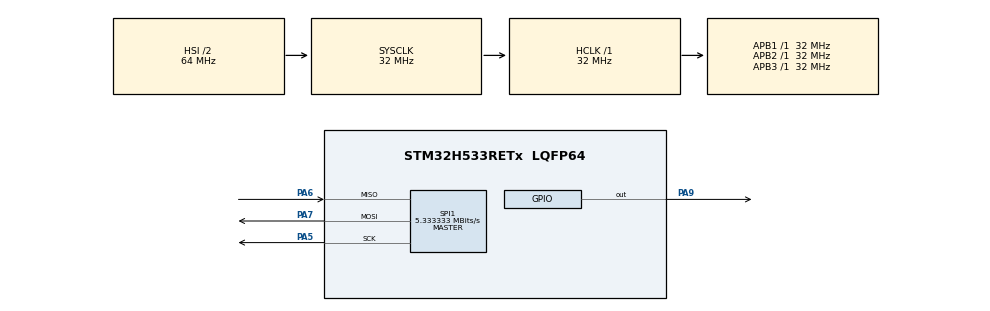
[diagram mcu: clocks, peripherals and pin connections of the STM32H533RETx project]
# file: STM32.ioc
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BOOTPATH.BootPathName=LEGACY
BOOTPATH.UserSelectedBootPath=LEGACY
CORTEX_M33_NS.Number-Cortex_Memory_Protection_Unit_Region0_OTP_RO_AREAS_Settings=MPU_REGION_NUMBER0
CORTEX_M33_NS.default_mode_Activation=1
CORTEX_M33_NS.userName=CORTEX_M33
Mcu.Family=STM32H5
Mcu.Name=STM32H533RETx
Mcu.Package=LQFP64
NUCLEO-H533RE.BUTTON=1
NUCLEO-H533RE.LD4=true
NUCLEO-H533RE.VCP=true
NVIC.EXTI13_IRQn=true\:0\:0\:false\:false\:true\:false\:true\:true
NVIC.PriorityGroup=NVIC_PRIORITYGROUP_4
PA13(JTMS/SWDIO).GPIO_Label=SWDIO
PA13(JTMS/SWDIO).Signal=DEBUG_JTMS-SWDIO
PA14(JTCK/SWCLK).GPIO_Label=SWCLK
PA14(JTCK/SWCLK).Signal=DEBUG_JTCK-SWCLK
PA15(JTDI).GPIO_Label=JTDI
PA15(JTDI).Signal=DEBUG_JTDI
PA2.Signal=USART2_TX
PA3.Signal=USART2_RX
PA5.Mode=Full_Duplex_Master
PA5.Signal=SPI1_SCK
PA6.Mode=Full_Duplex_Master
PA6.Signal=SPI1_MISO
PA7.Mode=Full_Duplex_Master
PA7.Signal=SPI1_MOSI
PA9.PinState=GPIO_PIN_SET
PA9.Signal=GPIO_Output
PB3(JTDO/TRACESWO).GPIO_Label=SWO
PB3(JTDO/TRACESWO).Signal=DEBUG_JTDO-SWO
ProjectManager.HeapSize=0x200
ProjectManager.StackSize=0x400
ProjectManager.TargetToolchain=CMake
RCC.ADCFreq_Value=32000000
RCC.AHBFreq_Value=32000000
RCC.APB1Freq_Value=32000000
RCC.APB1TimFreq_Value=32000000
RCC.APB2Freq_Value=32000000
RCC.APB2TimFreq_Value=32000000
RCC.APB3Freq_Value=32000000
RCC.CSI_VALUE=4000000
RCC.CortexFreq_Value=32000000
RCC.EPOD_VALUE=4000000
RCC.HCLKFreq_Value=32000000
RCC.HSE_VALUE=25000000
RCC.HSI48_VALUE=48000000
RCC.HSI_VALUE=64000000
RCC.LSE_VALUE=32768
RCC.LSIRC_VALUE=32000
RCC.PLL1Q=3
RCC.PLLFRACN=0
RCC.PLLN=32
RCC.SYSCLKFreq_VALUE=32000000
RCC.USBFreq_Value=48000000
RCC.VCOOutputFreq_Value=128000000
SPI1.BaudRatePrescaler=SPI_BAUDRATEPRESCALER_8
SPI1.CRCCalculation=SPI_CRCCALCULATION_DISABLE
SPI1.CalculateBaudRate=5.333333 MBits/s
SPI1.DataSize=SPI_DATASIZE_8BIT
SPI1.Direction=SPI_DIRECTION_2LINES
SPI1.MasterKeepIOState=SPI_MASTER_KEEP_IO_STATE_ENABLE
SPI1.MasterSSIdleness=SPI_MASTER_SS_IDLENESS_00CYCLE
SPI1.Mode=SPI_MODE_MASTER
SPI1.NSSPMode=SPI_NSS_PULSE_DISABLE
SPI1.VirtualType=VM_MASTER
VP_BOOTPATH_VS_BOOTPATH.Mode=BP_Activate
VP_CORTEX_M33_NS_VS_Hclk.Mode=Hclk_Mode
VP_ICACHE_VS_ICACHE.Mode=DirectMappedCache
VP_MEMORYMAP_VS_MEMORYMAP.Mode=CurAppReg
VP_NUCLEO-H533RE_VS_BSP_COMMON.Mode=COMMON
VP_PWR_VS_LPOM.Mode=PowerOptimisation
VP_PWR_VS_SECSignals.Mode=Security/Privilege
board=NUCLEO-H533RE

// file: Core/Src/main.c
/* USER CODE BEGIN Header */
/**
 ******************************************************************************
 * @file           : main.c
 * @brief          : Main program body
 ******************************************************************************
 * @attention
 *
 * Copyright (c) 2026 STMicroelectronics.
 * All rights reserved.
 *
 * This software is licensed under terms that can be found in the LICENSE file
 * in the root directory of this software component.
 * If no LICENSE file comes with this software, it is provided AS-IS.
 *
 ******************************************************************************
 */
/* USER CODE END Header */
#include "main.h"

/* USER CODE BEGIN Includes */
#include "../Inc/adxl367.h"
#include "../Inc/protocol.h"
#include "../Inc/uart.h"

/* USER CODE END Includes */

COM_InitTypeDef BspCOMInit;

SPI_HandleTypeDef hspi1;

void SystemClock_Config(void);
static void MPU_Config(void);
static void MX_GPIO_Init(void);
static void MX_ICACHE_Init(void);
static void MX_SPI1_Init(void);

int main(void) {

    /* MCU
     * Configuration--------------------------------------------------------*/

    /* MPU
     * Configuration--------------------------------------------------------*/
    MPU_Config();

    /* Reset of all peripherals, Initializes the Flash interface and the
     * Systick. */
    HAL_Init();

    /* Configure the system clock */
    SystemClock_Config();

    /* Initialize all configured peripherals */
    MX_GPIO_Init();
    MX_ICACHE_Init();
    MX_SPI1_Init();

    /* Initialize USER push-button, will be used to trigger an interrupt each
     * time it's pressed.*/
    BSP_PB_Init(BUTTON_USER, BUTTON_MODE_EXTI);

    /* Initialize COM1 port (115200, 8 bits (7-bit data + 1 stop bit), no parity
     */
    BspCOMInit.BaudRate = 115200;
    BspCOMInit.WordLength = COM_WORDLENGTH_8B;
    BspCOMInit.StopBits = COM_STOPBITS_1;
    BspCOMInit.Parity = COM_PARITY_NONE;
    BspCOMInit.HwFlowCtl = COM_HWCONTROL_NONE;
    if (BSP_COM_Init(COM1, &BspCOMInit) != BSP_ERROR_NONE) {
        Error_Handler();
    }

    /* Validate ADXL367 device id
     */
    uint8_t ADXL_Devid = 0;
    ADXL_Op(&hspi1, ADXL_READ, ADXL_DEVID_AD, &ADXL_Devid);

    ADXL_Init_Measure_Mode(&hspi1);

    uint8_t next_packet_seq = 0;
    /* Main Loop
     */
    while (1) {
        uint8_t data[6] = {};
        ADXL_Capture_Data(&hspi1, data);

        uint8_t* packet = Create_Packet(data, next_packet_seq);
        next_packet_seq = (next_packet_seq + 1) % 256;

        UART_Transmit(&hcom_uart[COM1], packet, 11);

        HAL_Delay(2.5);
    }
}

void SystemClock_Config(void) {
    RCC_OscInitTypeDef RCC_OscInitStruct = {0};
    RCC_ClkInitTypeDef RCC_ClkInitStruct = {0};

    /** Configure the main internal regulator output voltage
     */
    __HAL_PWR_VOLTAGESCALING_CONFIG(PWR_REGULATOR_VOLTAGE_SCALE3);

    while (!__HAL_PWR_GET_FLAG(PWR_FLAG_VOSRDY)) {
    }

    /** Initializes the RCC Oscillators according to the specified
     * parameters in the RCC_OscInitTypeDef structure.
     */
    RCC_OscInitStruct.OscillatorType =
        RCC_OSCILLATORTYPE_HSI | RCC_OSCILLATORTYPE_CSI;
    RCC_OscInitStruct.HSIState = RCC_HSI_ON;
    RCC_OscInitStruct.HSIDiv = RCC_HSI_DIV2;
    RCC_OscInitStruct.HSICalibrationValue = RCC_HSICALIBRATION_DEFAULT;
    RCC_OscInitStruct.CSIState = RCC_CSI_ON;
    RCC_OscInitStruct.CSICalibrationValue = RCC_CSICALIBRATION_DEFAULT;
    RCC_OscInitStruct.PLL.PLLState = RCC_PLL_ON;
    RCC_OscInitStruct.PLL.PLLSource = RCC_PLL1_SOURCE_CSI;
    RCC_OscInitStruct.PLL.PLLM = 1;
    RCC_OscInitStruct.PLL.PLLN = 32;
    RCC_OscInitStruct.PLL.PLLP = 2;
    RCC_OscInitStruct.PLL.PLLQ = 3;
    RCC_OscInitStruct.PLL.PLLR = 2;
    RCC_OscInitStruct.PLL.PLLRGE = RCC_PLL1_VCIRANGE_2;
    RCC_OscInitStruct.PLL.PLLVCOSEL = RCC_PLL1_VCORANGE_WIDE;
    RCC_OscInitStruct.PLL.PLLFRACN = 0;
    if (HAL_RCC_OscConfig(&RCC_OscInitStruct) != HAL_OK) {
        Error_Handler();
    }

    /** Initializes the CPU, AHB and APB buses clocks
     */
    RCC_ClkInitStruct.ClockType = RCC_CLOCKTYPE_HCLK | RCC_CLOCKTYPE_SYSCLK |
                                  RCC_CLOCKTYPE_PCLK1 | RCC_CLOCKTYPE_PCLK2 |
                                  RCC_CLOCKTYPE_PCLK3;
    RCC_ClkInitStruct.SYSCLKSource = RCC_SYSCLKSOURCE_HSI;
    RCC_ClkInitStruct.AHBCLKDivider = RCC_SYSCLK_DIV1;
    RCC_ClkInitStruct.APB1CLKDivider = RCC_HCLK_DIV1;
    RCC_ClkInitStruct.APB2CLKDivider = RCC_HCLK_DIV1;
    RCC_ClkInitStruct.APB3CLKDivider = RCC_HCLK_DIV1;

    if (HAL_RCC_ClockConfig(&RCC_ClkInitStruct, FLASH_LATENCY_1) != HAL_OK) {
        Error_Handler();
    }

    /** Configure the programming delay
     */
    __HAL_FLASH_SET_PROGRAM_DELAY(FLASH_PROGRAMMING_DELAY_0);
}

static void MX_ICACHE_Init(void) {

    /** Enable instruction cache in 1-way (direct mapped cache)
     */
    if (HAL_ICACHE_ConfigAssociativityMode(ICACHE_1WAY) != HAL_OK) {
        Error_Handler();
    }
    if (HAL_ICACHE_Enable() != HAL_OK) {
        Error_Handler();
    }
}

static void MX_SPI1_Init(void) {

    /* SPI1 parameter configuration*/
    hspi1.Instance = SPI1;
    hspi1.Init.Mode = SPI_MODE_MASTER;
    hspi1.Init.Direction = SPI_DIRECTION_2LINES;
    hspi1.Init.DataSize = SPI_DATASIZE_8BIT;
    hspi1.Init.CLKPolarity = SPI_POLARITY_LOW;
    hspi1.Init.CLKPhase = SPI_PHASE_1EDGE;
    hspi1.Init.NSS = SPI_NSS_SOFT;
    hspi1.Init.BaudRatePrescaler = SPI_BAUDRATEPRESCALER_8;
    hspi1.Init.FirstBit = SPI_FIRSTBIT_MSB;
    hspi1.Init.TIMode = SPI_TIMODE_DISABLE;
    hspi1.Init.CRCCalculation = SPI_CRCCALCULATION_DISABLE;
    hspi1.Init.CRCPolynomial = 0x7;
    hspi1.Init.NSSPMode = SPI_NSS_PULSE_DISABLE;
    hspi1.Init.NSSPolarity = SPI_NSS_POLARITY_LOW;
    hspi1.Init.FifoThreshold = SPI_FIFO_THRESHOLD_01DATA;
    hspi1.Init.MasterSSIdleness = SPI_MASTER_SS_IDLENESS_00CYCLE;
    hspi1.Init.MasterInterDataIdleness = SPI_MASTER_INTERDATA_IDLENESS_00CYCLE;
    hspi1.Init.MasterReceiverAutoSusp = SPI_MASTER_RX_AUTOSUSP_DISABLE;
    hspi1.Init.MasterKeepIOState = SPI_MASTER_KEEP_IO_STATE_ENABLE;
    hspi1.Init.IOSwap = SPI_IO_SWAP_DISABLE;
    hspi1.Init.ReadyMasterManagement = SPI_RDY_MASTER_MANAGEMENT_INTERNALLY;
    hspi1.Init.ReadyPolarity = SPI_RDY_POLARITY_HIGH;
    if (HAL_SPI_Init(&hspi1) != HAL_OK) {
        Error_Handler();
    }
}

static void MX_GPIO_Init(void) {
    GPIO_InitTypeDef GPIO_InitStruct = {0};

    /* GPIO Ports Clock Enable */
    __HAL_RCC_GPIOA_CLK_ENABLE();
    __HAL_RCC_GPIOB_CLK_ENABLE();

    /*Configure GPIO pin Output Level */
    HAL_GPIO_WritePin(GPIOA, GPIO_PIN_9, GPIO_PIN_SET);

    /*Configure GPIO pin : PA9 */
    GPIO_InitStruct.Pin = GPIO_PIN_9;
    GPIO_InitStruct.Mode = GPIO_MODE_OUTPUT_PP;
    GPIO_InitStruct.Pull = GPIO_NOPULL;
    GPIO_InitStruct.Speed = GPIO_SPEED_FREQ_LOW;
    HAL_GPIO_Init(GPIOA, &GPIO_InitStruct);

}

/* MPU Configuration */

void MPU_Config(void) {
    MPU_Region_InitTypeDef MPU_InitStruct = {0};
    MPU_Attributes_InitTypeDef MPU_AttributesInit = {0};

    /* Disables the MPU */
    HAL_MPU_Disable();

    /** Initializes and configures the Region 0 and the memory to be
     * protected
     */
    MPU_InitStruct.Enable = MPU_REGION_ENABLE;
    MPU_InitStruct.Number = MPU_REGION_NUMBER0;
    MPU_InitStruct.BaseAddress = 0x08FFF000;
    MPU_InitStruct.LimitAddress = 0x08FFFFFF;
    MPU_InitStruct.AttributesIndex = MPU_ATTRIBUTES_NUMBER0;
    MPU_InitStruct.AccessPermission = MPU_REGION_ALL_RO;
    MPU_InitStruct.DisableExec = MPU_INSTRUCTION_ACCESS_DISABLE;
    MPU_InitStruct.IsShareable = MPU_ACCESS_NOT_SHAREABLE;

    HAL_MPU_ConfigRegion(&MPU_InitStruct);

    /** Initializes and configures the Attribute 0 and the memory to be
     * protected
     */
    MPU_AttributesInit.Number = MPU_ATTRIBUTES_NUMBER0;
    MPU_AttributesInit.Attributes = INNER_OUTER(MPU_NOT_CACHEABLE);

    HAL_MPU_ConfigMemoryAttributes(&MPU_AttributesInit);
    /* Enables the MPU */
    HAL_MPU_Enable(MPU_PRIVILEGED_DEFAULT);
}

void Error_Handler(void) {
    /* USER CODE BEGIN Error_Handler_Debug */
    /* User can add his own implementation to report the HAL error return
     * state
     */
    __disable_irq();
    while (1) {
    }
    /* USER CODE END Error_Handler_Debug */
}
#ifdef USE_FULL_ASSERT
/**
 * @brief  Reports the name of the source file and the source line number
 *         where the assert_param error has occurred.
 * @param  file: pointer to the source file name
 * @param  line: assert_param error line source number
 * @retval None
 */
void assert_failed(uint8_t* file, uint32_t line) {
    /* USER CODE BEGIN 6 */
    /* User can add his own implementation to report the file name and line
       number, ex: printf("Wrong parameters value: file %s on line %d\r\n",
       file, line) */
    /* USER CODE END 6 */
}
#endif /* USE_FULL_ASSERT */
